VERSION ""

NS_ :

BS_:

BU_:

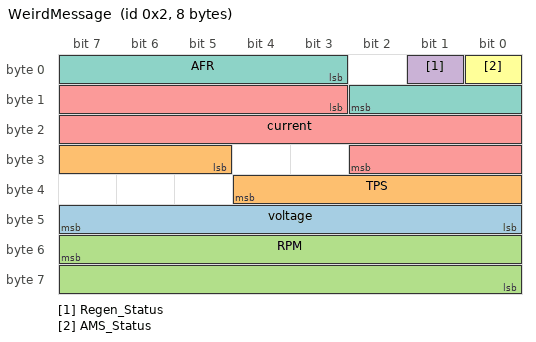
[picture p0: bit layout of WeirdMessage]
BO_ 2 WeirdMessage: 8 Vector__XXX
 SG_ voltage : 47|8@0+ (0.1,0) [0|25.5] "" Vector__XXX
 SG_ TPS : 29|8@1+ (0.5,0) [0|127.5] "" Vector__XXX
 SG_ RPM : 55|16@0+ (1,0) [0|65535] "" Vector__XXX
 SG_ Regen_Status : 1|1@1+ (1,0) [0|1] "" Vector__XXX
 SG_ current : 11|16@1- (1,0) [-128|127] "" Vector__XXX
 SG_ AMS_Status : 0|1@1+ (1,0) [0|1] "" Vector__XXX
 SG_ AFR : 3|8@1+ (0.1,0) [0|25.5] "" Vector__XXX
